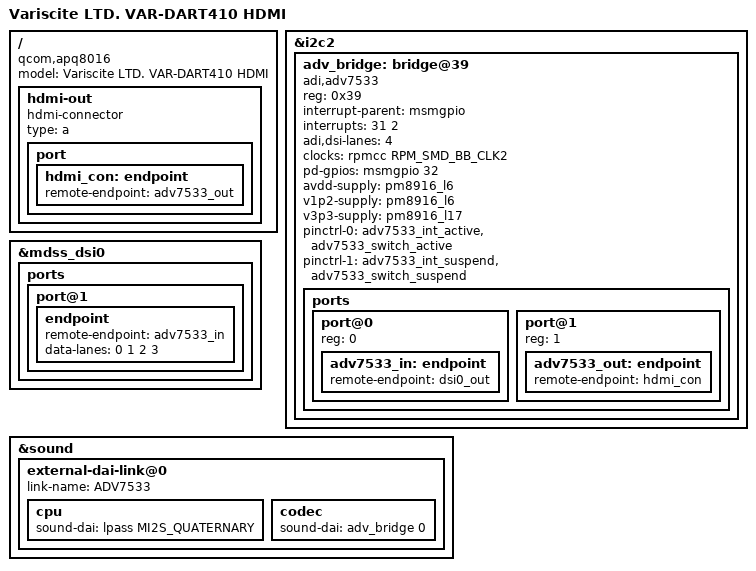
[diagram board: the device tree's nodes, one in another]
/*
 * Copyright (c) 2015, The Linux Foundation. All rights reserved.
 *
 * This program is free software; you can redistribute it and/or modify
 * it under the terms of the GNU General Public License version 2 and
 * only version 2 as published by the Free Software Foundation.
 *
 * This program is distributed in the hope that it will be useful,
 * but WITHOUT ANY WARRANTY; without even the implied warranty of
 * MERCHANTABILITY or FITNESS FOR A PARTICULAR PURPOSE.  See the
 * GNU General Public License for more details.
 */

/dts-v1/;
#include "apq8016-var-dart.dtsi"

/ {
	model = "Variscite LTD. VAR-DART410 HDMI";
	compatible ="qcom,apq8016", "variscite,dart-sd410";

	hdmi-out {
		compatible = "hdmi-connector";
		type = "a";

		port {
			hdmi_con: endpoint {
				remote-endpoint = <&adv7533_out>;
			};
		};
	};
};

&i2c2 {
	adv_bridge: bridge@39 {
		status = "okay";

		compatible = "adi,adv7533";
		reg = <0x39>;

		interrupt-parent = <&msmgpio>;
		interrupts = <31 2>;

		adi,dsi-lanes = <4>;
		clocks = <&rpmcc RPM_SMD_BB_CLK2>;
		clock-names = "cec";

		pd-gpios = <&msmgpio 32 GPIO_ACTIVE_HIGH>;

		avdd-supply = <&pm8916_l6>;
		v1p2-supply = <&pm8916_l6>;
		v3p3-supply = <&pm8916_l17>;

		pinctrl-names = "default","sleep";
		pinctrl-0 = <&adv7533_int_active &adv7533_switch_active>;
		pinctrl-1 = <&adv7533_int_suspend &adv7533_switch_suspend>;
		#sound-dai-cells = <1>;

		ports {
			#address-cells = <1>;
			#size-cells = <0>;

			port@0 {
				reg = <0>;
				adv7533_in: endpoint {
					remote-endpoint = <&dsi0_out>;
				};
			};

			port@1 {
				reg = <1>;
				adv7533_out: endpoint {
					remote-endpoint = <&hdmi_con>;
				};
			};
		};
	};
};

&mdss_dsi0 {
	ports {
		port@1 {
			endpoint {
				remote-endpoint = <&adv7533_in>;
				data-lanes = <0 1 2 3>;
			};
		};
	};
};

&sound {
	external-dai-link@0 {
		link-name = "ADV7533";
		cpu { /* QUAT */
			sound-dai = <&lpass MI2S_QUATERNARY>;
		};
		codec {
			sound-dai = <&adv_bridge 0>;
		};
	};
};
